# STM32H7B3xxQ register map
File version: 1.0
Registers are 32-bit, read-write, reset 0x0 unless marked. A register's access mark holds for its fields unless they carry their own. Offsets are from the block's base; [hi:lo] are bit positions; {n}, {i} and the like mark numbered series.

## EXTI — External Interrupt/Event Controller
Base 0x58000000
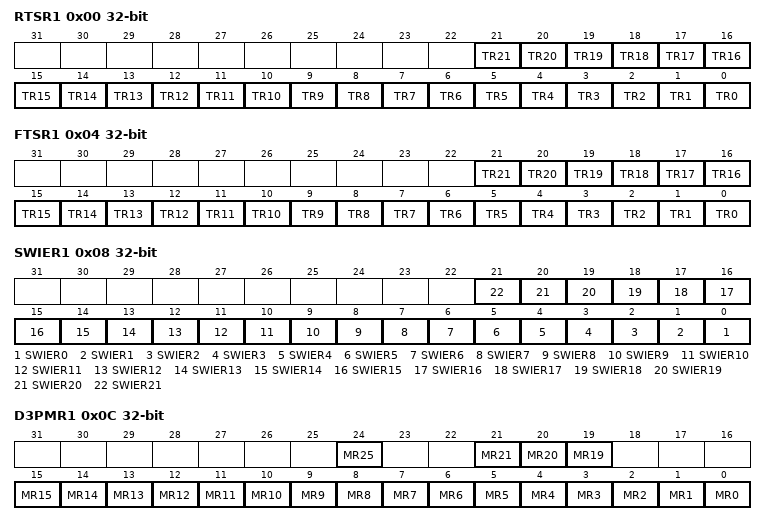
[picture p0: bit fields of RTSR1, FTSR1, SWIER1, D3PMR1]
0x00 RTSR1 — EXTI Rising trigger selection register
  [n] TR{n} (n=0..21) — Rising trigger event configuration bit of line {n}
0x04 FTSR1 — EXTI Falling trigger selection register
  [n] TR{n} (n=0..21) — Falling trigger event configuration bit of line {n}
0x08 SWIER1 — EXTI Software interrupt event register
  [n] SWIER{n} (n=0..21) — Software Interrupt on line {n}
0x0C D3PMR1 — EXTI D3 Pending mask register, (same register as to SRDPMR1)
  [24] MR25 — Pending Mask Event for line 25
  [21] MR21 — Pending Mask Event for line 21
  [20] MR20 — Pending Mask Event for line 20
  [19] MR19 — Pending Mask Event for line 19
  [n] MR{n} (n=0..15) — Pending Mask Event for line {n}
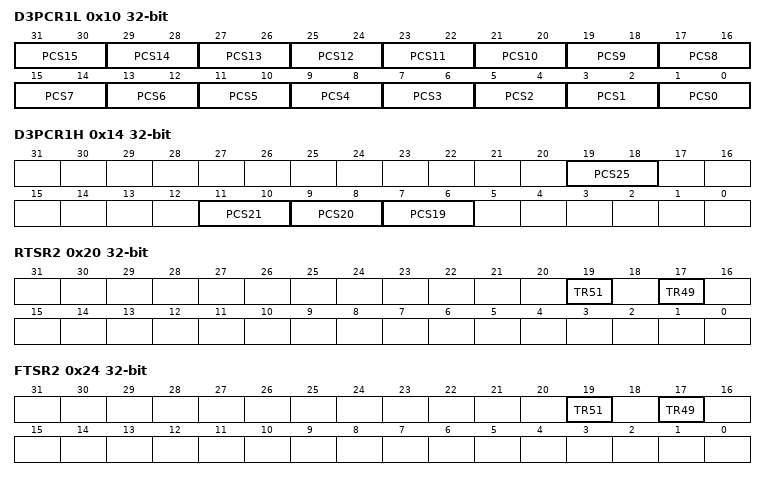
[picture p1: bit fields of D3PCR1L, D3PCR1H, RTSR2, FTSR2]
0x10 D3PCR1L — EXTI D3 Pending clear selection register low, (same register as to SRDPCR1L)
  [2n+1:2n] PCS{n} (n=0..15) — D3 Pending request clear input signal selection on line {n}
0x14 D3PCR1H — EXTI D3 Pending clear selection register High, (same register as to SRDPCR1H)
  [19:18] PCS25 — D3 Pending request clear input signal selection on line 25
  [11:10] PCS21 — D3 Pending request clear input signal selection on line 21
  [9:8] PCS20 — D3 Pending request clear input signal selection on line 20
  [7:6] PCS19 — D3 Pending request clear input signal selection on line 19
0x20 RTSR2 — EXTI Rising trigger selection register
  [19] TR51 — Rising trigger event configuration bit of line 51
  [17] TR49 — Rising trigger event configuration bit of line 49
0x24 FTSR2 — EXTI Falling trigger selection register
  [19] TR51 — Falling trigger event configuration bit of line 51
  [17] TR49 — Falling trigger event configuration bit of line 49
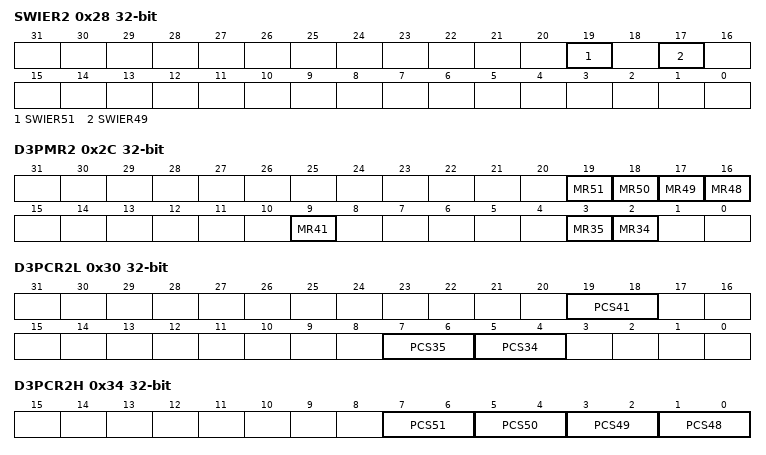
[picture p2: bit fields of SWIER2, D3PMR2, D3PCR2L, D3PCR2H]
0x28 SWIER2 — EXTI Software interrupt event register
  [19] SWIER51 — Software Interrupt on line 51
  [17] SWIER49 — Software Interrupt on line 49
0x2C D3PMR2 — EXTI D3 Pending mask register, (same register as to SRDPMR2)
  [n-32] MR{n} (n=48..51) — Pending Mask Event for line {n}
  [9] MR41 — Pending Mask Event for line 41
  [3] MR35 — Pending Mask Event for line 35
  [2] MR34 — Pending Mask Event for line 34
0x30 D3PCR2L — EXTI D3 Pending clear selection register low, (same register as to SRDPCR2L)
  [19:18] PCS41 — D3 Pending request clear input signal selection on line 41
  [7:6] PCS35 — D3 Pending request clear input signal selection on line 35
  [5:4] PCS34 — D3 Pending request clear input signal selection on line 34
0x34 D3PCR2H — EXTI D3 Pending clear selection register High, (same register as to SRDPCR2H)
  [2n-95:2n-96] PCS{n} (n=48..51) — D3 Pending request clear input signal selection on line {n}
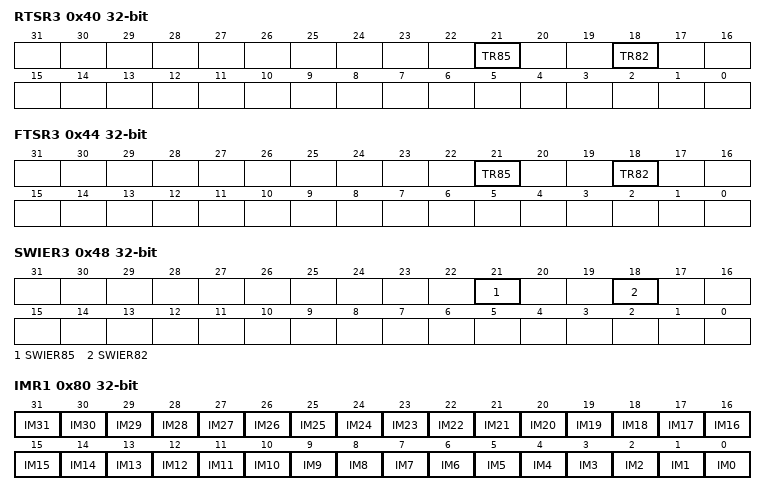
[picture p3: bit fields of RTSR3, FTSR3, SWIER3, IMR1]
0x40 RTSR3 — EXTI Rising trigger selection register
  [21] TR85 — Rising trigger event configuration bit of line 85
  [18] TR82 — Rising trigger event configuration bit of line 82
0x44 FTSR3 — EXTI Falling trigger selection register
  [21] TR85 — Falling trigger event configuration bit of line 85
  [18] TR82 — Falling trigger event configuration bit of line 82
0x48 SWIER3 — EXTI Software interrupt event register
  [21] SWIER85 — Software Interrupt on line 85
  [18] SWIER82 — Software Interrupt on line 82
0x4C D3PMR3 — EXTI D3 Pending mask register, (same register as to SRDPMR3)
  [24] MR88 — Pending Mask Event for line 88
0x50 D3PCR3L — EXTI D3 Pending clear selection register low, (same register as to SRDPCR3L)
0x54 D3PCR3H — EXTI D3 Pending clear selection register High, (same register as to SRDPCR3H)
  [17:16] PCS88 — D3 Pending request clear input signal selection on line 88
0x80 IMR1 — EXTI Interrupt mask register
  [n] IM{n} (n=0..31) — Interrupt Mask on line {n}
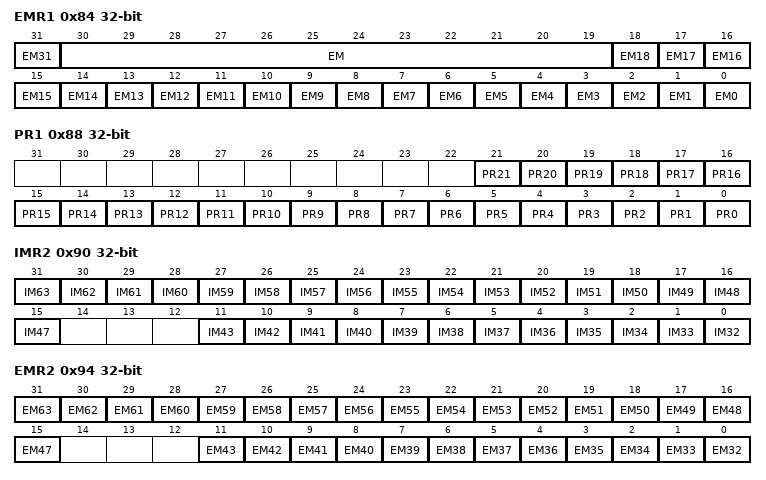
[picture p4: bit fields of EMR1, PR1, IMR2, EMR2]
0x84 EMR1 — EXTI Event mask register
  [31] EM31 — Event Mask on line 31
  [30:19] EM — Event Mask
  [n] EM{n} (n=0..18) — Event Mask on line {n}
0x88 PR1 — EXTI Pending register
  [n] PR{n} (n=0..21) — Pending bit for line {n}
0x90 IMR2 — EXTI Interrupt mask register
  [n-32] IM{n} (n=47..63) — Interrupt Mask on line {n}
  [n-32] IM{n} (n=32..43) — Interrupt Mask on line {n}
0x94 EMR2 — EXTI Event mask register
  [n-32] EM{n} (n=47..63) — Event Mask on line {n}
  [n-32] EM{n} (n=32..43) — Event Mask on line {n}
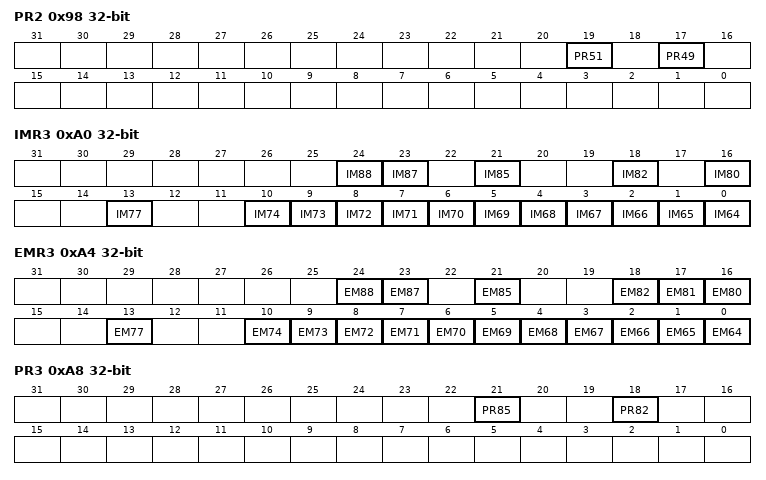
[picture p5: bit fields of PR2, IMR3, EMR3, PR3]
0x98 PR2 — EXTI Pending register
  [19] PR51 — Pending bit for line 51
  [17] PR49 — Pending bit for line 49
0xA0 IMR3 — EXTI Interrupt mask register
  [24] IM88 — Interrupt Mask on line 88
  [23] IM87 — Interrupt Mask on line 87
  [21] IM85 — Interrupt Mask on line 85
  [18] IM82 — Interrupt Mask on line 82
  [16] IM80 — Interrupt Mask on line 80
  [13] IM77 — Interrupt Mask on line 77
  [n-64] IM{n} (n=64..74) — Interrupt Mask on line {n}
0xA4 EMR3 — EXTI Event mask register
  [24] EM88 — Event Mask on line 88
  [23] EM87 — Event Mask on line 87
  [21] EM85 — Event Mask on line 85
  [18] EM82 — Event Mask on line 82
  [17] EM81 — Event Mask on line 81
  [16] EM80 — Event Mask on line 80
  [13] EM77 — Event Mask on line 77
  [n-64] EM{n} (n=64..74) — Event Mask on line {n}
0xA8 PR3 — EXTI Pending register
  [21] PR85 — Pending bit for line 85
  [18] PR82 — Pending bit for line 82
